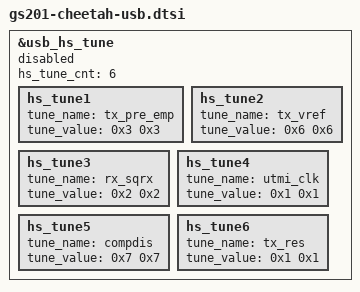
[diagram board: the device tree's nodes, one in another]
// SPDX-License-Identifier: GPL-2.0-only
/*
 * Google Oriole USB device tree source
 *
 * Copyright 2022 Google,LLC
 */

&usb_hs_tune {
	status = "disabled";
	hs_tune_cnt = <6>;
	/* value = <device host> */
	hs_tune1 {
		tune_name = "tx_pre_emp";
		tune_value = <0x3 0x3>;
	};

	hs_tune2 {
		tune_name = "tx_vref";
		tune_value = <0x6 0x6>;
	};

	hs_tune3 {
		tune_name = "rx_sqrx";
		tune_value = <0x2 0x2>;
	};

	hs_tune4 {
		tune_name = "utmi_clk";
		tune_value = <0x1 0x1>;
	};

	hs_tune5 {
		tune_name = "compdis";
		tune_value = <0x7 0x7>;
	};

	hs_tune6 {
		tune_name = "tx_res";
		tune_value = <0x1 0x1>;
	};
};
